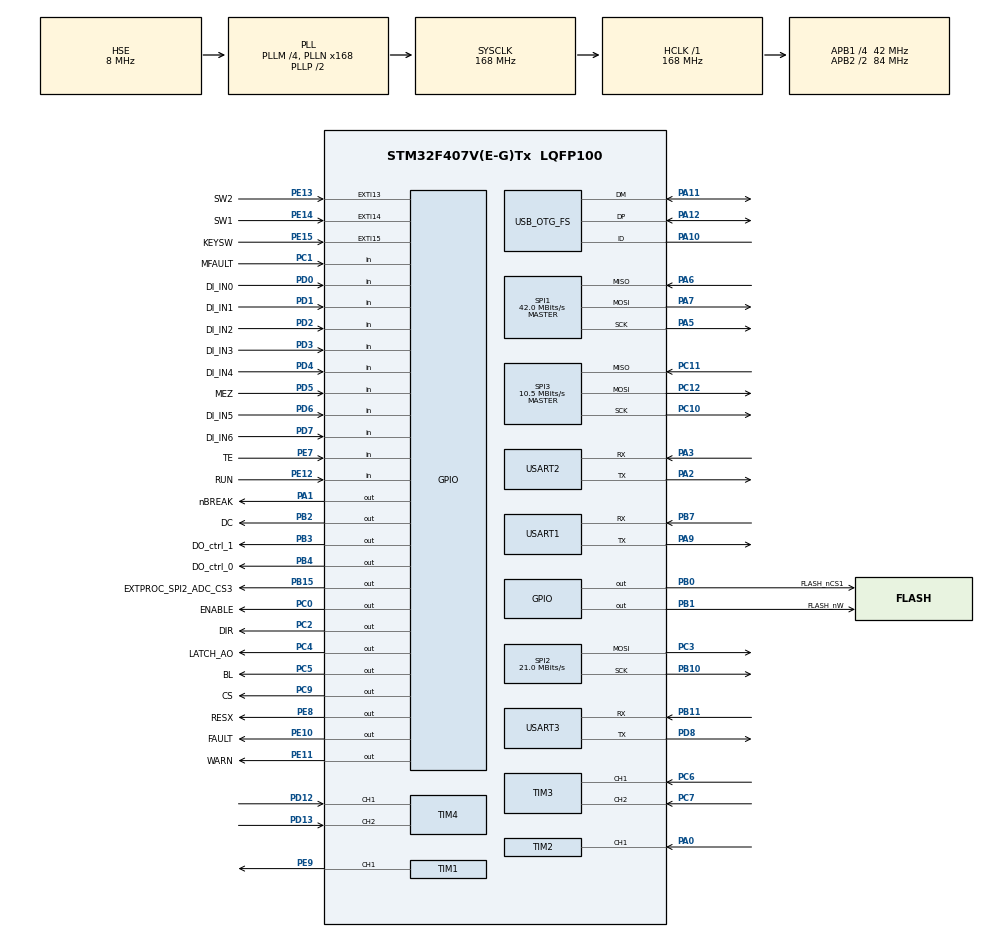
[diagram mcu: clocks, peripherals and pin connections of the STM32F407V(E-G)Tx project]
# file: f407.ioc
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Dma.Request0=SPI1_RX
Dma.Request1=USART1_RX
Dma.SPI1_RX.0.Direction=DMA_PERIPH_TO_MEMORY
Dma.SPI1_RX.0.FIFOMode=DMA_FIFOMODE_DISABLE
Dma.SPI1_RX.0.Instance=DMA2_Stream0
Dma.SPI1_RX.0.MemDataAlignment=DMA_MDATAALIGN_BYTE
Dma.SPI1_RX.0.MemInc=DMA_MINC_ENABLE
Dma.SPI1_RX.0.Mode=DMA_NORMAL
Dma.SPI1_RX.0.PeriphDataAlignment=DMA_PDATAALIGN_BYTE
Dma.SPI1_RX.0.PeriphInc=DMA_PINC_DISABLE
Dma.SPI1_RX.0.Priority=DMA_PRIORITY_LOW
Dma.USART1_RX.1.Direction=DMA_PERIPH_TO_MEMORY
Dma.USART1_RX.1.FIFOMode=DMA_FIFOMODE_DISABLE
Dma.USART1_RX.1.Instance=DMA2_Stream2
Dma.USART1_RX.1.MemDataAlignment=DMA_MDATAALIGN_BYTE
Dma.USART1_RX.1.MemInc=DMA_MINC_ENABLE
Dma.USART1_RX.1.Mode=DMA_NORMAL
Dma.USART1_RX.1.PeriphDataAlignment=DMA_PDATAALIGN_BYTE
Dma.USART1_RX.1.PeriphInc=DMA_PINC_DISABLE
Dma.USART1_RX.1.Priority=DMA_PRIORITY_LOW
Mcu.Family=STM32F4
Mcu.Name=STM32F407V(E-G)Tx
Mcu.Package=LQFP100
NVIC.DMA2_Stream0_IRQn=true\:0\:0\:false\:false\:true\:false\:true\:true
NVIC.DMA2_Stream2_IRQn=true\:0\:0\:false\:false\:true\:false\:true\:true
NVIC.PriorityGroup=NVIC_PRIORITYGROUP_4
NVIC.TIM3_IRQn=true\:0\:0\:false\:false\:true\:true\:true\:true
NVIC.TIM4_IRQn=true\:0\:0\:false\:false\:true\:true\:true\:true
NVIC.USART1_IRQn=true\:0\:0\:false\:false\:true\:true\:true\:true
PA0-WKUP.Signal=S_TIM2_CH1_ETR
PA1.GPIO_Label=nBREAK
PA1.Signal=GPIO_Output
PA10.Mode=OTG/Dual_Role_Device
PA10.Signal=USB_OTG_FS_ID
PA11.Mode=OTG/Dual_Role_Device
PA11.Signal=USB_OTG_FS_DM
PA12.Mode=OTG/Dual_Role_Device
PA12.Signal=USB_OTG_FS_DP
PA13.Mode=Serial_Wire
PA13.Signal=SYS_JTMS-SWDIO
PA14.Mode=Serial_Wire
PA14.Signal=SYS_JTCK-SWCLK
PA2.Mode=Asynchronous
PA2.Signal=USART2_TX
PA3.Mode=Asynchronous
PA3.Signal=USART2_RX
PA5.Mode=Full_Duplex_Master
PA5.Signal=SPI1_SCK
PA6.Mode=Full_Duplex_Master
PA6.Signal=SPI1_MISO
PA7.Mode=Full_Duplex_Master
PA7.Signal=SPI1_MOSI
PA9.Mode=Asynchronous
PA9.Signal=USART1_TX
PB0.GPIO_Label=FLASH_nCS1
PB0.PinState=GPIO_PIN_SET
PB0.Signal=GPIO_Output
PB1.GPIO_Label=FLASH_nW
PB1.PinState=GPIO_PIN_SET
PB1.Signal=GPIO_Output
PB10.Mode=TX_Only_Simplex_Unidirect_Master
PB10.Signal=SPI2_SCK
PB11.Mode=Asynchronous
PB11.Signal=USART3_RX
PB15.GPIO_Label=EXTPROC_SPI2_ADC_CS3
PB15.PinState=GPIO_PIN_SET
PB15.Signal=GPIO_Output
PB2.GPIO_Label=DC
PB2.Signal=GPIO_Output
PB3.GPIO_Label=DO_ctrl_1
PB3.Signal=GPIO_Output
PB4.GPIO_Label=DO_ctrl_0
PB4.Signal=GPIO_Output
PB7.Mode=Asynchronous
PB7.Signal=USART1_RX
PC0.GPIO_Label=ENABLE
PC0.Signal=GPIO_Output
PC1.GPIO_Label=MFAULT
PC1.Signal=GPIO_Input
PC10.Mode=Full_Duplex_Master
PC10.Signal=SPI3_SCK
PC11.Mode=Full_Duplex_Master
PC11.Signal=SPI3_MISO
PC12.Mode=Full_Duplex_Master
PC12.Signal=SPI3_MOSI
PC14-OSC32_IN.Mode=LSE-External-Oscillator
PC14-OSC32_IN.Signal=RCC_OSC32_IN
PC15-OSC32_OUT.Mode=LSE-External-Oscillator
PC15-OSC32_OUT.Signal=RCC_OSC32_OUT
PC2.GPIO_Label=DIR
PC2.Signal=GPIO_Output
PC3.Mode=TX_Only_Simplex_Unidirect_Master
PC3.Signal=SPI2_MOSI
PC4.GPIO_Label=LATCH_AO
PC4.Signal=GPIO_Output
PC5.GPIO_Label=BL
PC5.Signal=GPIO_Output
PC6.Signal=S_TIM3_CH1
PC7.Signal=S_TIM3_CH2
PC9.GPIO_Label=CS
PC9.GPIO_Speed=GPIO_SPEED_FREQ_HIGH
PC9.PinState=GPIO_PIN_SET
PC9.Signal=GPIO_Output
PD0.GPIO_Label=DI_IN0
PD0.Signal=GPIO_Input
PD1.GPIO_Label=DI_IN1
PD1.Signal=GPIO_Input
PD12.Signal=S_TIM4_CH1
PD13.Signal=S_TIM4_CH2
PD2.GPIO_Label=DI_IN2
PD2.Signal=GPIO_Input
PD3.GPIO_Label=DI_IN3
PD3.Signal=GPIO_Input
PD4.GPIO_Label=DI_IN4
PD4.Signal=GPIO_Input
PD5.GPIO_Label=MEZ
PD5.Signal=GPIO_Input
PD6.GPIO_Label=DI_IN5
PD6.Signal=GPIO_Input
PD7.GPIO_Label=DI_IN6
PD7.Signal=GPIO_Input
PD8.Mode=Asynchronous
PD8.Signal=USART3_TX
PE10.GPIO_Label=FAULT
PE10.Signal=GPIO_Output
PE11.GPIO_Label=WARN
PE11.Signal=GPIO_Output
PE12.GPIO_Label=RUN
PE12.Signal=GPIO_Input
PE13.GPIO_Label=SW2
PE13.GPIO_ModeDefaultEXTI=GPIO_MODE_IT_FALLING
PE13.Signal=GPXTI13
PE14.GPIO_Label=SW1
PE14.GPIO_ModeDefaultEXTI=GPIO_MODE_IT_FALLING
PE14.Signal=GPXTI14
PE15.GPIO_Label=KEYSW
PE15.GPIO_ModeDefaultEXTI=GPIO_MODE_IT_FALLING
PE15.Signal=GPXTI15
PE7.GPIO_Label=TE
PE7.Signal=GPIO_Input
PE8.GPIO_Label=RESX
PE8.Signal=GPIO_Output
PE9.Signal=S_TIM1_CH1
PH0-OSC_IN.Mode=HSE-External-Oscillator
PH0-OSC_IN.Signal=RCC_OSC_IN
PH1-OSC_OUT.Mode=HSE-External-Oscillator
PH1-OSC_OUT.Signal=RCC_OSC_OUT
ProjectManager.HeapSize=0x200
ProjectManager.StackSize=0x400
ProjectManager.TargetToolchain=MDK-ARM V5.32
RCC.48MHZClocksFreq_Value=48000000
RCC.AHBFreq_Value=168000000
RCC.APB1CLKDivider=RCC_HCLK_DIV4
RCC.APB1Freq_Value=42000000
RCC.APB1TimFreq_Value=84000000
RCC.APB2CLKDivider=RCC_HCLK_DIV2
RCC.APB2Freq_Value=84000000
RCC.APB2TimFreq_Value=168000000
RCC.CortexFreq_Value=168000000
RCC.HCLKFreq_Value=168000000
RCC.HSE_VALUE=8000000
RCC.HSI_VALUE=16000000
RCC.PLLM=4
RCC.PLLN=168
RCC.PLLQ=7
RCC.SYSCLKFreq_VALUE=168000000
RCC.SYSCLKSource=RCC_SYSCLKSOURCE_PLLCLK
RCC.VCOOutputFreq_Value=336000000
SH.S_TIM1_CH1.0=TIM1_CH1,PWM Generation1 CH1
SH.S_TIM2_CH1_ETR.0=TIM2_CH1,Input_Capture1_from_TI1
SH.S_TIM3_CH1.0=TIM3_CH1,Encoder_Interface
SH.S_TIM3_CH2.0=TIM3_CH2,Encoder_Interface
SH.S_TIM4_CH1.0=TIM4_CH1,Encoder_Interface
SH.S_TIM4_CH2.0=TIM4_CH2,Encoder_Interface
SPI1.CalculateBaudRate=42.0 MBits/s
SPI1.Direction=SPI_DIRECTION_2LINES
SPI1.Mode=SPI_MODE_MASTER
SPI1.VirtualType=VM_MASTER
SPI2.CalculateBaudRate=21.0 MBits/s
SPI2.Direction=SPI_DIRECTION_2LINES
SPI2.Mode=SPI_MODE_MASTER
SPI2.VirtualType=VM_MASTER
SPI3.BaudRatePrescaler=SPI_BAUDRATEPRESCALER_4
SPI3.CLKPolarity=SPI_POLARITY_HIGH
SPI3.CalculateBaudRate=10.5 MBits/s
SPI3.Direction=SPI_DIRECTION_2LINES
SPI3.Mode=SPI_MODE_MASTER
SPI3.VirtualType=VM_MASTER
TIM1.Channel-PWM\ Generation1\ CH1=TIM_CHANNEL_1
TIM2.Channel-Input_Capture1_from_TI1=TIM_CHANNEL_1
TIM3.EncoderMode=TIM_ENCODERMODE_TI12
TIM3.IC1Filter=4
TIM3.IC2Filter=4
TIM4.EncoderMode=TIM_ENCODERMODE_TI12
TIM4.IC1Filter=4
USART1.VirtualMode=VM_ASYNC
USART2.VirtualMode=VM_ASYNC
USART3.VirtualMode=VM_ASYNC
VP_RTC_VS_RTC_Activate.Mode=RTC_Enabled
VP_TIM1_VS_ClockSourceINT.Mode=Internal
VP_TIM2_VS_ClockSourceINT.Mode=Internal
board=custom

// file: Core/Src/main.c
/* USER CODE BEGIN Header */
/**
  ******************************************************************************
  * @file           : main.c
  * @brief          : Main program body
  ******************************************************************************
  * @attention
  *
  * Copyright (c) 2026 STMicroelectronics.
  * All rights reserved.
  *
  * This software is licensed under terms that can be found in the LICENSE file
  * in the root directory of this software component.
  * If no LICENSE file comes with this software, it is provided AS-IS.
  *
  ******************************************************************************
  */
/* USER CODE END Header */
#include "main.h"

/* USER CODE BEGIN Includes */
#include "bsp_encoder.h"
/* USER CODE END Includes */

RTC_HandleTypeDef hrtc;

SPI_HandleTypeDef hspi1;
SPI_HandleTypeDef hspi2;
SPI_HandleTypeDef hspi3;
DMA_HandleTypeDef hdma_spi1_rx;

TIM_HandleTypeDef htim1;
TIM_HandleTypeDef htim2;
TIM_HandleTypeDef htim3;
TIM_HandleTypeDef htim4;

UART_HandleTypeDef huart1;
UART_HandleTypeDef huart2;
UART_HandleTypeDef huart3;
DMA_HandleTypeDef hdma_usart1_rx;

void SystemClock_Config(void);
static void MX_GPIO_Init(void);
static void MX_DMA_Init(void);
static void MX_RTC_Init(void);
static void MX_SPI1_Init(void);
static void MX_SPI2_Init(void);
static void MX_SPI3_Init(void);
static void MX_TIM1_Init(void);
static void MX_TIM2_Init(void);
static void MX_TIM3_Init(void);
static void MX_TIM4_Init(void);
static void MX_USART1_UART_Init(void);
static void MX_USART2_UART_Init(void);
static void MX_USART3_UART_Init(void);
static void MX_USB_OTG_FS_USB_Init(void);

/* USER CODE BEGIN 0 */
void HAL_TIM_PeriodElapsedCallback(TIM_HandleTypeDef *htim) {

  if (htim->Instance == TIM2) {

  encoder_over_flow();
  }
}
void HAL_GPIO_EXTI_Callback(uint16_t GPIO_Pin)
{
	if (GPIO_Pin == KEYSW_Pin)
	{
      get_button()->enter = 1;
	}
}

/* USER CODE END 0 */

int main(void)
{

  /* MCU Configuration--------------------------------------------------------*/

  /* Reset of all peripherals, Initializes the Flash interface and the Systick. */
  HAL_Init();

  /* Configure the system clock */
  SystemClock_Config();

  /* Initialize all configured peripherals */
  MX_GPIO_Init();
  MX_DMA_Init();
  MX_RTC_Init();
  MX_SPI1_Init();
  MX_SPI2_Init();
  MX_SPI3_Init();
  MX_TIM1_Init();
  MX_TIM2_Init();
  MX_TIM3_Init();
  MX_TIM4_Init();
  MX_USART1_UART_Init();
  MX_USART2_UART_Init();
  MX_USART3_UART_Init();
  MX_USB_OTG_FS_USB_Init();

  /* Infinite loop */
  while (1)
  {

  }
}

void SystemClock_Config(void)
{
  RCC_OscInitTypeDef RCC_OscInitStruct = {0};
  RCC_ClkInitTypeDef RCC_ClkInitStruct = {0};

  /** Configure the main internal regulator output voltage
  */
  __HAL_RCC_PWR_CLK_ENABLE();
  __HAL_PWR_VOLTAGESCALING_CONFIG(PWR_REGULATOR_VOLTAGE_SCALE1);

  /** Initializes the RCC Oscillators according to the specified parameters
  * in the RCC_OscInitTypeDef structure.
  */
  RCC_OscInitStruct.OscillatorType = RCC_OSCILLATORTYPE_LSI|RCC_OSCILLATORTYPE_HSE;
  RCC_OscInitStruct.HSEState = RCC_HSE_ON;
  RCC_OscInitStruct.LSIState = RCC_LSI_ON;
  RCC_OscInitStruct.PLL.PLLState = RCC_PLL_ON;
  RCC_OscInitStruct.PLL.PLLSource = RCC_PLLSOURCE_HSE;
  RCC_OscInitStruct.PLL.PLLM = 4;
  RCC_OscInitStruct.PLL.PLLN = 168;
  RCC_OscInitStruct.PLL.PLLP = RCC_PLLP_DIV2;
  RCC_OscInitStruct.PLL.PLLQ = 7;
  if (HAL_RCC_OscConfig(&RCC_OscInitStruct) != HAL_OK)
  {
    Error_Handler();
  }

  /** Initializes the CPU, AHB and APB buses clocks
  */
  RCC_ClkInitStruct.ClockType = RCC_CLOCKTYPE_HCLK|RCC_CLOCKTYPE_SYSCLK
                              |RCC_CLOCKTYPE_PCLK1|RCC_CLOCKTYPE_PCLK2;
  RCC_ClkInitStruct.SYSCLKSource = RCC_SYSCLKSOURCE_PLLCLK;
  RCC_ClkInitStruct.AHBCLKDivider = RCC_SYSCLK_DIV1;
  RCC_ClkInitStruct.APB1CLKDivider = RCC_HCLK_DIV4;
  RCC_ClkInitStruct.APB2CLKDivider = RCC_HCLK_DIV2;

  if (HAL_RCC_ClockConfig(&RCC_ClkInitStruct, FLASH_LATENCY_5) != HAL_OK)
  {
    Error_Handler();
  }
}

static void MX_RTC_Init(void)
{

  /** Initialize RTC Only
  */
  hrtc.Instance = RTC;
  hrtc.Init.HourFormat = RTC_HOURFORMAT_24;
  hrtc.Init.AsynchPrediv = 127;
  hrtc.Init.SynchPrediv = 255;
  hrtc.Init.OutPut = RTC_OUTPUT_DISABLE;
  hrtc.Init.OutPutPolarity = RTC_OUTPUT_POLARITY_HIGH;
  hrtc.Init.OutPutType = RTC_OUTPUT_TYPE_OPENDRAIN;
  if (HAL_RTC_Init(&hrtc) != HAL_OK)
  {
    Error_Handler();
  }

}

static void MX_SPI1_Init(void)
{

  /* SPI1 parameter configuration*/
  hspi1.Instance = SPI1;
  hspi1.Init.Mode = SPI_MODE_MASTER;
  hspi1.Init.Direction = SPI_DIRECTION_2LINES;
  hspi1.Init.DataSize = SPI_DATASIZE_8BIT;
  hspi1.Init.CLKPolarity = SPI_POLARITY_LOW;
  hspi1.Init.CLKPhase = SPI_PHASE_1EDGE;
  hspi1.Init.NSS = SPI_NSS_SOFT;
  hspi1.Init.BaudRatePrescaler = SPI_BAUDRATEPRESCALER_2;
  hspi1.Init.FirstBit = SPI_FIRSTBIT_MSB;
  hspi1.Init.TIMode = SPI_TIMODE_DISABLE;
  hspi1.Init.CRCCalculation = SPI_CRCCALCULATION_DISABLE;
  hspi1.Init.CRCPolynomial = 10;
  if (HAL_SPI_Init(&hspi1) != HAL_OK)
  {
    Error_Handler();
  }

}

static void MX_SPI2_Init(void)
{

  /* SPI2 parameter configuration*/
  hspi2.Instance = SPI2;
  hspi2.Init.Mode = SPI_MODE_MASTER;
  hspi2.Init.Direction = SPI_DIRECTION_2LINES;
  hspi2.Init.DataSize = SPI_DATASIZE_8BIT;
  hspi2.Init.CLKPolarity = SPI_POLARITY_LOW;
  hspi2.Init.CLKPhase = SPI_PHASE_1EDGE;
  hspi2.Init.NSS = SPI_NSS_SOFT;
  hspi2.Init.BaudRatePrescaler = SPI_BAUDRATEPRESCALER_2;
  hspi2.Init.FirstBit = SPI_FIRSTBIT_MSB;
  hspi2.Init.TIMode = SPI_TIMODE_DISABLE;
  hspi2.Init.CRCCalculation = SPI_CRCCALCULATION_DISABLE;
  hspi2.Init.CRCPolynomial = 10;
  if (HAL_SPI_Init(&hspi2) != HAL_OK)
  {
    Error_Handler();
  }

}

static void MX_SPI3_Init(void)
{

  /* SPI3 parameter configuration*/
  hspi3.Instance = SPI3;
  hspi3.Init.Mode = SPI_MODE_MASTER;
  hspi3.Init.Direction = SPI_DIRECTION_2LINES;
  hspi3.Init.DataSize = SPI_DATASIZE_8BIT;
  hspi3.Init.CLKPolarity = SPI_POLARITY_HIGH;
  hspi3.Init.CLKPhase = SPI_PHASE_1EDGE;
  hspi3.Init.NSS = SPI_NSS_SOFT;
  hspi3.Init.BaudRatePrescaler = SPI_BAUDRATEPRESCALER_4;
  hspi3.Init.FirstBit = SPI_FIRSTBIT_MSB;
  hspi3.Init.TIMode = SPI_TIMODE_DISABLE;
  hspi3.Init.CRCCalculation = SPI_CRCCALCULATION_DISABLE;
  hspi3.Init.CRCPolynomial = 10;
  if (HAL_SPI_Init(&hspi3) != HAL_OK)
  {
    Error_Handler();
  }

}

static void MX_TIM1_Init(void)
{

  TIM_ClockConfigTypeDef sClockSourceConfig = {0};
  TIM_MasterConfigTypeDef sMasterConfig = {0};
  TIM_OC_InitTypeDef sConfigOC = {0};
  TIM_BreakDeadTimeConfigTypeDef sBreakDeadTimeConfig = {0};

  htim1.Instance = TIM1;
  htim1.Init.Prescaler = 0;
  htim1.Init.CounterMode = TIM_COUNTERMODE_UP;
  htim1.Init.Period = 65535;
  htim1.Init.ClockDivision = TIM_CLOCKDIVISION_DIV1;
  htim1.Init.RepetitionCounter = 0;
  htim1.Init.AutoReloadPreload = TIM_AUTORELOAD_PRELOAD_DISABLE;
  if (HAL_TIM_Base_Init(&htim1) != HAL_OK)
  {
    Error_Handler();
  }
  sClockSourceConfig.ClockSource = TIM_CLOCKSOURCE_INTERNAL;
  if (HAL_TIM_ConfigClockSource(&htim1, &sClockSourceConfig) != HAL_OK)
  {
    Error_Handler();
  }
  if (HAL_TIM_PWM_Init(&htim1) != HAL_OK)
  {
    Error_Handler();
  }
  sMasterConfig.MasterOutputTrigger = TIM_TRGO_RESET;
  sMasterConfig.MasterSlaveMode = TIM_MASTERSLAVEMODE_DISABLE;
  if (HAL_TIMEx_MasterConfigSynchronization(&htim1, &sMasterConfig) != HAL_OK)
  {
    Error_Handler();
  }
  sConfigOC.OCMode = TIM_OCMODE_PWM1;
  sConfigOC.Pulse = 0;
  sConfigOC.OCPolarity = TIM_OCPOLARITY_HIGH;
  sConfigOC.OCNPolarity = TIM_OCNPOLARITY_HIGH;
  sConfigOC.OCFastMode = TIM_OCFAST_DISABLE;
  sConfigOC.OCIdleState = TIM_OCIDLESTATE_RESET;
  sConfigOC.OCNIdleState = TIM_OCNIDLESTATE_RESET;
  if (HAL_TIM_PWM_ConfigChannel(&htim1, &sConfigOC, TIM_CHANNEL_1) != HAL_OK)
  {
    Error_Handler();
  }
  sBreakDeadTimeConfig.OffStateRunMode = TIM_OSSR_DISABLE;
  sBreakDeadTimeConfig.OffStateIDLEMode = TIM_OSSI_DISABLE;
  sBreakDeadTimeConfig.LockLevel = TIM_LOCKLEVEL_OFF;
  sBreakDeadTimeConfig.DeadTime = 0;
  sBreakDeadTimeConfig.BreakState = TIM_BREAK_DISABLE;
  sBreakDeadTimeConfig.BreakPolarity = TIM_BREAKPOLARITY_HIGH;
  sBreakDeadTimeConfig.AutomaticOutput = TIM_AUTOMATICOUTPUT_DISABLE;
  if (HAL_TIMEx_ConfigBreakDeadTime(&htim1, &sBreakDeadTimeConfig) != HAL_OK)
  {
    Error_Handler();
  }
  HAL_TIM_MspPostInit(&htim1);

}

static void MX_TIM2_Init(void)
{

  TIM_ClockConfigTypeDef sClockSourceConfig = {0};
  TIM_MasterConfigTypeDef sMasterConfig = {0};
  TIM_IC_InitTypeDef sConfigIC = {0};

  htim2.Instance = TIM2;
  htim2.Init.Prescaler = 0;
  htim2.Init.CounterMode = TIM_COUNTERMODE_UP;
  htim2.Init.Period = 4294967295;
  htim2.Init.ClockDivision = TIM_CLOCKDIVISION_DIV1;
  htim2.Init.AutoReloadPreload = TIM_AUTORELOAD_PRELOAD_DISABLE;
  if (HAL_TIM_Base_Init(&htim2) != HAL_OK)
  {
    Error_Handler();
  }
  sClockSourceConfig.ClockSource = TIM_CLOCKSOURCE_INTERNAL;
  if (HAL_TIM_ConfigClockSource(&htim2, &sClockSourceConfig) != HAL_OK)
  {
    Error_Handler();
  }
  if (HAL_TIM_IC_Init(&htim2) != HAL_OK)
  {
    Error_Handler();
  }
  sMasterConfig.MasterOutputTrigger = TIM_TRGO_RESET;
  sMasterConfig.MasterSlaveMode = TIM_MASTERSLAVEMODE_DISABLE;
  if (HAL_TIMEx_MasterConfigSynchronization(&htim2, &sMasterConfig) != HAL_OK)
  {
    Error_Handler();
  }
  sConfigIC.ICPolarity = TIM_INPUTCHANNELPOLARITY_RISING;
  sConfigIC.ICSelection = TIM_ICSELECTION_DIRECTTI;
  sConfigIC.ICPrescaler = TIM_ICPSC_DIV1;
  sConfigIC.ICFilter = 0;
  if (HAL_TIM_IC_ConfigChannel(&htim2, &sConfigIC, TIM_CHANNEL_1) != HAL_OK)
  {
    Error_Handler();
  }

}

static void MX_TIM3_Init(void)
{

  TIM_Encoder_InitTypeDef sConfig = {0};
  TIM_MasterConfigTypeDef sMasterConfig = {0};

  htim3.Instance = TIM3;
  htim3.Init.Prescaler = 0;
  htim3.Init.CounterMode = TIM_COUNTERMODE_UP;
  htim3.Init.Period = 65535;
  htim3.Init.ClockDivision = TIM_CLOCKDIVISION_DIV1;
  htim3.Init.AutoReloadPreload = TIM_AUTORELOAD_PRELOAD_DISABLE;
  sConfig.EncoderMode = TIM_ENCODERMODE_TI12;
  sConfig.IC1Polarity = TIM_ICPOLARITY_RISING;
  sConfig.IC1Selection = TIM_ICSELECTION_DIRECTTI;
  sConfig.IC1Prescaler = TIM_ICPSC_DIV1;
  sConfig.IC1Filter = 4;
  sConfig.IC2Polarity = TIM_ICPOLARITY_RISING;
  sConfig.IC2Selection = TIM_ICSELECTION_DIRECTTI;
  sConfig.IC2Prescaler = TIM_ICPSC_DIV1;
  sConfig.IC2Filter = 4;
  if (HAL_TIM_Encoder_Init(&htim3, &sConfig) != HAL_OK)
  {
    Error_Handler();
  }
  sMasterConfig.MasterOutputTrigger = TIM_TRGO_RESET;
  sMasterConfig.MasterSlaveMode = TIM_MASTERSLAVEMODE_DISABLE;
  if (HAL_TIMEx_MasterConfigSynchronization(&htim3, &sMasterConfig) != HAL_OK)
  {
    Error_Handler();
  }

}

static void MX_TIM4_Init(void)
{

  TIM_Encoder_InitTypeDef sConfig = {0};
  TIM_MasterConfigTypeDef sMasterConfig = {0};

  htim4.Instance = TIM4;
  htim4.Init.Prescaler = 0;
  htim4.Init.CounterMode = TIM_COUNTERMODE_UP;
  htim4.Init.Period = 65535;
  htim4.Init.ClockDivision = TIM_CLOCKDIVISION_DIV1;
  htim4.Init.AutoReloadPreload = TIM_AUTORELOAD_PRELOAD_DISABLE;
  sConfig.EncoderMode = TIM_ENCODERMODE_TI12;
  sConfig.IC1Polarity = TIM_ICPOLARITY_RISING;
  sConfig.IC1Selection = TIM_ICSELECTION_DIRECTTI;
  sConfig.IC1Prescaler = TIM_ICPSC_DIV1;
  sConfig.IC1Filter = 4;
  sConfig.IC2Polarity = TIM_ICPOLARITY_RISING;
  sConfig.IC2Selection = TIM_ICSELECTION_DIRECTTI;
  sConfig.IC2Prescaler = TIM_ICPSC_DIV1;
  sConfig.IC2Filter = 0;
  if (HAL_TIM_Encoder_Init(&htim4, &sConfig) != HAL_OK)
  {
    Error_Handler();
  }
  sMasterConfig.MasterOutputTrigger = TIM_TRGO_RESET;
  sMasterConfig.MasterSlaveMode = TIM_MASTERSLAVEMODE_DISABLE;
  if (HAL_TIMEx_MasterConfigSynchronization(&htim4, &sMasterConfig) != HAL_OK)
  {
    Error_Handler();
  }

}

static void MX_USART1_UART_Init(void)
{

  huart1.Instance = USART1;
  huart1.Init.BaudRate = 115200;
  huart1.Init.WordLength = UART_WORDLENGTH_8B;
  huart1.Init.StopBits = UART_STOPBITS_1;
  huart1.Init.Parity = UART_PARITY_NONE;
  huart1.Init.Mode = UART_MODE_TX_RX;
  huart1.Init.HwFlowCtl = UART_HWCONTROL_NONE;
  huart1.Init.OverSampling = UART_OVERSAMPLING_16;
  if (HAL_UART_Init(&huart1) != HAL_OK)
  {
    Error_Handler();
  }

}

static void MX_USART2_UART_Init(void)
{

  huart2.Instance = USART2;
  huart2.Init.BaudRate = 115200;
  huart2.Init.WordLength = UART_WORDLENGTH_8B;
  huart2.Init.StopBits = UART_STOPBITS_1;
  huart2.Init.Parity = UART_PARITY_NONE;
  huart2.Init.Mode = UART_MODE_TX_RX;
  huart2.Init.HwFlowCtl = UART_HWCONTROL_NONE;
  huart2.Init.OverSampling = UART_OVERSAMPLING_16;
  if (HAL_UART_Init(&huart2) != HAL_OK)
  {
    Error_Handler();
  }

}

static void MX_USART3_UART_Init(void)
{

  huart3.Instance = USART3;
  huart3.Init.BaudRate = 115200;
  huart3.Init.WordLength = UART_WORDLENGTH_8B;
  huart3.Init.StopBits = UART_STOPBITS_1;
  huart3.Init.Parity = UART_PARITY_NONE;
  huart3.Init.Mode = UART_MODE_TX_RX;
  huart3.Init.HwFlowCtl = UART_HWCONTROL_NONE;
  huart3.Init.OverSampling = UART_OVERSAMPLING_16;
  if (HAL_UART_Init(&huart3) != HAL_OK)
  {
    Error_Handler();
  }

}

static void MX_USB_OTG_FS_USB_Init(void)
{

}

static void MX_DMA_Init(void)
{

  /* DMA controller clock enable */
  __HAL_RCC_DMA2_CLK_ENABLE();

  /* DMA interrupt init */
  /* DMA2_Stream0_IRQn interrupt configuration */
  HAL_NVIC_SetPriority(DMA2_Stream0_IRQn, 0, 0);
  HAL_NVIC_EnableIRQ(DMA2_Stream0_IRQn);
  /* DMA2_Stream2_IRQn interrupt configuration */
  HAL_NVIC_SetPriority(DMA2_Stream2_IRQn, 0, 0);
  HAL_NVIC_EnableIRQ(DMA2_Stream2_IRQn);

}

static void MX_GPIO_Init(void)
{
  GPIO_InitTypeDef GPIO_InitStruct = {0};

  /* GPIO Ports Clock Enable */
  __HAL_RCC_GPIOC_CLK_ENABLE();
  __HAL_RCC_GPIOH_CLK_ENABLE();
  __HAL_RCC_GPIOA_CLK_ENABLE();
  __HAL_RCC_GPIOB_CLK_ENABLE();
  __HAL_RCC_GPIOE_CLK_ENABLE();
  __HAL_RCC_GPIOD_CLK_ENABLE();

  /*Configure GPIO pin Output Level */
  HAL_GPIO_WritePin(GPIOC, ENABLE_Pin|DIR_Pin|LATCH_AO_Pin|BL_Pin, GPIO_PIN_RESET);

  /*Configure GPIO pin Output Level */
  HAL_GPIO_WritePin(nBREAK_GPIO_Port, nBREAK_Pin, GPIO_PIN_RESET);

  /*Configure GPIO pin Output Level */
  HAL_GPIO_WritePin(GPIOB, FLASH_nCS1_Pin|FLASH_nW_Pin|EXTPROC_SPI2_ADC_CS3_Pin, GPIO_PIN_SET);

  /*Configure GPIO pin Output Level */
  HAL_GPIO_WritePin(GPIOB, DC_Pin|DO_ctrl_1_Pin|DO_ctrl_0_Pin, GPIO_PIN_RESET);

  /*Configure GPIO pin Output Level */
  HAL_GPIO_WritePin(GPIOE, RESX_Pin|FAULT_Pin|WARN_Pin, GPIO_PIN_RESET);

  /*Configure GPIO pin Output Level */
  HAL_GPIO_WritePin(CS_GPIO_Port, CS_Pin, GPIO_PIN_SET);

  /*Configure GPIO pins : ENABLE_Pin DIR_Pin LATCH_AO_Pin BL_Pin */
  GPIO_InitStruct.Pin = ENABLE_Pin|DIR_Pin|LATCH_AO_Pin|BL_Pin;
  GPIO_InitStruct.Mode = GPIO_MODE_OUTPUT_PP;
  GPIO_InitStruct.Pull = GPIO_NOPULL;
  GPIO_InitStruct.Speed = GPIO_SPEED_FREQ_LOW;
  HAL_GPIO_Init(GPIOC, &GPIO_InitStruct);

  /*Configure GPIO pin : MFAULT_Pin */
  GPIO_InitStruct.Pin = MFAULT_Pin;
  GPIO_InitStruct.Mode = GPIO_MODE_INPUT;
  GPIO_InitStruct.Pull = GPIO_NOPULL;
  HAL_GPIO_Init(MFAULT_GPIO_Port, &GPIO_InitStruct);

  /*Configure GPIO pin : nBREAK_Pin */
  GPIO_InitStruct.Pin = nBREAK_Pin;
  GPIO_InitStruct.Mode = GPIO_MODE_OUTPUT_PP;
  GPIO_InitStruct.Pull = GPIO_NOPULL;
  GPIO_InitStruct.Speed = GPIO_SPEED_FREQ_LOW;
  HAL_GPIO_Init(nBREAK_GPIO_Port, &GPIO_InitStruct);

  /*Configure GPIO pins : FLASH_nCS1_Pin FLASH_nW_Pin DC_Pin EXTPROC_SPI2_ADC_CS3_Pin
                           DO_ctrl_1_Pin DO_ctrl_0_Pin */
  GPIO_InitStruct.Pin = FLASH_nCS1_Pin|FLASH_nW_Pin|DC_Pin|EXTPROC_SPI2_ADC_CS3_Pin
                          |DO_ctrl_1_Pin|DO_ctrl_0_Pin;
  GPIO_InitStruct.Mode = GPIO_MODE_OUTPUT_PP;
  GPIO_InitStruct.Pull = GPIO_NOPULL;
  GPIO_InitStruct.Speed = GPIO_SPEED_FREQ_LOW;
  HAL_GPIO_Init(GPIOB, &GPIO_InitStruct);

  /*Configure GPIO pins : TE_Pin RUN_Pin */
  GPIO_InitStruct.Pin = TE_Pin|RUN_Pin;
  GPIO_InitStruct.Mode = GPIO_MODE_INPUT;
  GPIO_InitStruct.Pull = GPIO_NOPULL;
  HAL_GPIO_Init(GPIOE, &GPIO_InitStruct);

  /*Configure GPIO pins : RESX_Pin FAULT_Pin WARN_Pin */
  GPIO_InitStruct.Pin = RESX_Pin|FAULT_Pin|WARN_Pin;
  GPIO_InitStruct.Mode = GPIO_MODE_OUTPUT_PP;
  GPIO_InitStruct.Pull = GPIO_NOPULL;
  GPIO_InitStruct.Speed = GPIO_SPEED_FREQ_LOW;
  HAL_GPIO_Init(GPIOE, &GPIO_InitStruct);

  /*Configure GPIO pins : SW2_Pin SW1_Pin KEYSW_Pin */
  GPIO_InitStruct.Pin = SW2_Pin|SW1_Pin|KEYSW_Pin;
  GPIO_InitStruct.Mode = GPIO_MODE_IT_FALLING;
  GPIO_InitStruct.Pull = GPIO_NOPULL;
  HAL_GPIO_Init(GPIOE, &GPIO_InitStruct);

  /*Configure GPIO pin : CS_Pin */
  GPIO_InitStruct.Pin = CS_Pin;
  GPIO_InitStruct.Mode = GPIO_MODE_OUTPUT_PP;
  GPIO_InitStruct.Pull = GPIO_NOPULL;
  GPIO_InitStruct.Speed = GPIO_SPEED_FREQ_HIGH;
  HAL_GPIO_Init(CS_GPIO_Port, &GPIO_InitStruct);

  /*Configure GPIO pins : PA10 PA11 PA12 */
  GPIO_InitStruct.Pin = GPIO_PIN_10|GPIO_PIN_11|GPIO_PIN_12;
  GPIO_InitStruct.Mode = GPIO_MODE_AF_PP;
  GPIO_InitStruct.Pull = GPIO_NOPULL;
  GPIO_InitStruct.Speed = GPIO_SPEED_FREQ_VERY_HIGH;
  GPIO_InitStruct.Alternate = GPIO_AF10_OTG_FS;
  HAL_GPIO_Init(GPIOA, &GPIO_InitStruct);

  /*Configure GPIO pins : DI_IN0_Pin DI_IN1_Pin DI_IN2_Pin DI_IN3_Pin
                           DI_IN4_Pin MEZ_Pin DI_IN5_Pin DI_IN6_Pin */
  GPIO_InitStruct.Pin = DI_IN0_Pin|DI_IN1_Pin|DI_IN2_Pin|DI_IN3_Pin
                          |DI_IN4_Pin|MEZ_Pin|DI_IN5_Pin|DI_IN6_Pin;
  GPIO_InitStruct.Mode = GPIO_MODE_INPUT;
  GPIO_InitStruct.Pull = GPIO_NOPULL;
  HAL_GPIO_Init(GPIOD, &GPIO_InitStruct);

}

void Error_Handler(void)
{
  __disable_irq();
  while (1)
  {
  }
}
